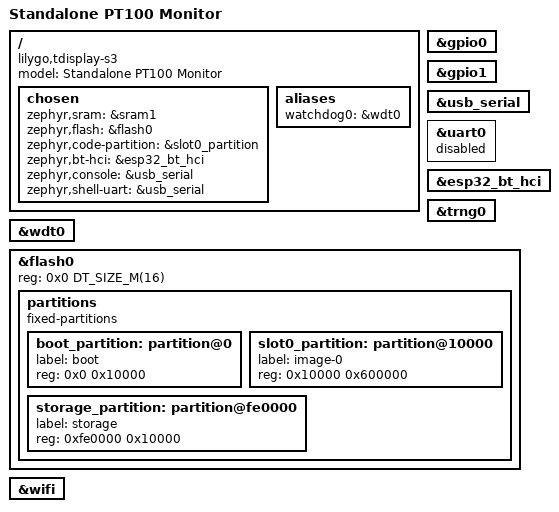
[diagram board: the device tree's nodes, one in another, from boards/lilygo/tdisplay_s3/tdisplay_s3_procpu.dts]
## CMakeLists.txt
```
cmake_minimum_required(VERSION 3.20.0)
# Validate on every configure, including direct west/CMake builds.
find_program(PROBE_CONFIG_PYTHON NAMES python3 REQUIRED)
execute_process(COMMAND ${PROBE_CONFIG_PYTHON} ${CMAKE_CURRENT_SOURCE_DIR}/tools/configure.py
  RESULT_VARIABLE PROBE_CONFIG_RESULT)
if(NOT PROBE_CONFIG_RESULT EQUAL 0)
  message(FATAL_ERROR "Fill config/device.json before building or flashing (see README.md).")
endif()
list(APPEND BOARD_ROOT ${CMAKE_CURRENT_SOURCE_DIR})
find_package(Zephyr REQUIRED HINTS $ENV{ZEPHYR_BASE})
project(thermal_probe)
target_sources(app PRIVATE src/main.c src/wireless.c src/modbus_codec.c src/http_request.c src/filter.c src/format.c)
target_sources_ifdef(CONFIG_THERMAL_DISPLAY app PRIVATE src/display.c src/tdisplay_lcd.c)
target_include_directories(app PRIVATE ${CMAKE_CURRENT_SOURCE_DIR}/local)
```

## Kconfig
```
mainmenu "Thermal Probe"

source "Kconfig.zephyr"

menu "Thermal Probe options"

config THERMAL_DISPLAY
    bool "Enable the tested ST7789 panel and GPIO14 controls"
    default y
    help
      Disable for a headless build on the same supported ESP32-S3 board.
      Sensor, power enable and network behavior remain unchanged.

endmenu
```

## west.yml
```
manifest:
  projects:
    - name: zephyr
      url: https://github.com/zephyrproject-rtos/zephyr
      revision: v4.1.0
      import:
        name-allowlist:
          - hal_espressif
          - hal_xtensa
          - mbedtls
  self:
    path: thermal-probe
```

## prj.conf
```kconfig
CONFIG_GPIO=y
CONFIG_MAIN_STACK_SIZE=8192
CONFIG_NEWLIB_LIBC=y
CONFIG_NEWLIB_LIBC_FLOAT_PRINTF=y
CONFIG_BUILD_OUTPUT_BIN=y
CONFIG_ESP_SIMPLE_BOOT=y
CONFIG_BOOTLOADER_MCUBOOT=n
CONFIG_SMP=n
CONFIG_ESPTOOLPY_FLASHSIZE_16MB=y
CONFIG_ESPTOOLPY_FLASHFREQ_40M=y
CONFIG_BT=n
CONFIG_WIFI=y
CONFIG_ESP_SPIRAM=n
CONFIG_HEAP_MEM_POOL_SIZE=98304

CONFIG_NETWORKING=y
CONFIG_NET_IPV4=y
CONFIG_NET_IPV6=n
CONFIG_NET_TCP=y
CONFIG_NET_UDP=y
CONFIG_NET_DHCPV4=y
CONFIG_NET_SOCKETS=y
CONFIG_NET_MGMT=y
CONFIG_NET_MGMT_EVENT=y
CONFIG_NET_MGMT_EVENT_INFO=y
CONFIG_ESP32_WIFI_STA_AUTO_DHCPV4=y
CONFIG_ESP32_WIFI_STA_RECONNECT=y
CONFIG_NET_MAX_CONTEXTS=32
CONFIG_NET_PKT_RX_COUNT=48
CONFIG_NET_PKT_TX_COUNT=48
CONFIG_NET_BUF_RX_COUNT=64
CONFIG_NET_BUF_TX_COUNT=64

CONFIG_NET_L2_ETHERNET=y

# Two listeners, six clients, DHCP and reconnect headroom.
CONFIG_ZVFS_OPEN_MAX=16
CONFIG_NET_MAX_CONN=32

# Required for worker timeout/slot reclamation; setsockopt otherwise fails.
CONFIG_NET_CONTEXT_RCVTIMEO=y
CONFIG_NET_CONTEXT_SNDTIMEO=y

# LAN discovery and serial diagnostics.
CONFIG_NET_ARP_TABLE_SIZE=8
CONFIG_NET_ARP_GRATUITOUS_TRANSMISSION=y
CONFIG_NET_ARP_GRATUITOUS_INTERVAL=10
CONFIG_NET_STATISTICS=y
CONFIG_NET_STATISTICS_USER_API=y

CONFIG_LOG=y
CONFIG_LOG_DEFAULT_LEVEL=2
CONFIG_LOG_BUFFER_SIZE=2048
CONFIG_LOG_PROCESS_THREAD_STACK_SIZE=2048
CONFIG_NET_LOG=y
CONFIG_NET_ARP_LOG_LEVEL_WRN=y
CONFIG_NET_TCP_LOG_LEVEL_WRN=y

# Each TCP context reserves RX/TX packet descriptors, including listeners.
# Leave descriptors and full Ethernet frame buffers available during reconnects.
CONFIG_NET_BUF_DATA_SIZE=256
CONFIG_NET_TCP_MAX_RECV_WINDOW_SIZE=1280
CONFIG_NET_TCP_MAX_SEND_WINDOW_SIZE=1280
CONFIG_NET_TCP_RETRY_COUNT=3
```

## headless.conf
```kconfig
# Same board and sensor contract; omit panel driver, UI thread and history.
CONFIG_THERMAL_DISPLAY=n
```

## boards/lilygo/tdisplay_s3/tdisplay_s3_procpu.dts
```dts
/dts-v1/;
#include <espressif/esp32s3/esp32s3_wroom_n8.dtsi>
#include <zephyr/dt-bindings/gpio/gpio.h>

/ {
    model = "Standalone PT100 Monitor";
    compatible = "lilygo,tdisplay-s3";
    chosen {
        zephyr,sram = &sram1;
        zephyr,flash = &flash0;
        zephyr,code-partition = &slot0_partition;
        zephyr,bt-hci = &esp32_bt_hci;
        zephyr,console = &usb_serial;
        zephyr,shell-uart = &usb_serial;

    };
    aliases { watchdog0 = &wdt0; };

};
&gpio0 { status = "okay"; };
&gpio1 { status = "okay"; };
&usb_serial { status = "okay"; };
&uart0 { status = "disabled"; };
&esp32_bt_hci { status = "okay"; };
&trng0 { status = "okay"; };
&wdt0 { status = "okay"; };
&flash0 {
    reg = <0x0 DT_SIZE_M(16)>;
    partitions {
        compatible = "fixed-partitions";
        #address-cells = <1>; #size-cells = <1>;
        boot_partition: partition@0 { label = "boot"; reg = <0x0 0x10000>; };
        slot0_partition: partition@10000 { label = "image-0"; reg = <0x10000 0x600000>; };
        storage_partition: partition@fe0000 { label = "storage"; reg = <0xfe0000 0x10000>; };
    };
};

&wifi { status = "okay"; };
```

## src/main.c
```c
#include <zephyr/kernel.h>
#include <zephyr/drivers/gpio.h>
#include <math.h>
#include "format.h"
#include <stdlib.h>
#include <string.h>
#include "wireless.h"
#include "filter.h"
#include "display.h"

static const struct device *gpio=DEVICE_DT_GET(DT_NODELABEL(gpio0));
enum {CS=10,MOSI=11,SCK=12,MISO=13,BUTTON=14};
static void set(int p,int v){gpio_pin_set(gpio,p,v);}
/* MAX31865 SPI mode 1: clock idle low, data sampled on falling edge. */
static unsigned transfer(unsigned v){unsigned r=0;for(int i=7;i>=0;i--){set(SCK,1);set(MOSI,(v>>i)&1);k_busy_wait(2);set(SCK,0);k_busy_wait(2);r=(r<<1)|(gpio_pin_get(gpio,MISO)>0);}return r;}
static void write_reg(unsigned addr,unsigned val){set(CS,0);transfer(addr|128);transfer(val);set(CS,1);}
static unsigned read_reg(unsigned addr){set(CS,0);transfer(addr);unsigned r=transfer(0);set(CS,1);return r;}
static bool temperature(double *t){
 /* Bias + continuous + 3-wire + 50 Hz mains rejection. Readback catches missing chip. */
 if((read_reg(0)&0xd1)!=0xd1){write_reg(0,0xd3);return false;}
 set(CS,0);transfer(1);unsigned raw=transfer(0)<<8;raw|=transfer(0);set(CS,1);
 if((raw&1)||read_reg(7)){write_reg(0,0xd3);return false;}
 double r=(raw>>1)*430.0/32768.0;
 if(r<18.5||r>390.5)return false;
 /* Invert IEC 60751 including the negative-temperature C term. */
 double lo=-200,hi=850;
 for(int i=0;i<32;i++){double x=(lo+hi)/2;double rr=100*(1+3.9083e-3*x-5.775e-7*x*x+(x<0?-4.183e-12*(x-100)*x*x*x:0));if(rr<r)lo=x;else hi=x;}
 *t=(lo+hi)/2;return true;
}
int main(void){
 gpio_pin_configure(gpio,15,GPIO_OUTPUT_HIGH);
 gpio_pin_configure(gpio,CS,GPIO_OUTPUT_HIGH);gpio_pin_configure(gpio,MOSI,GPIO_OUTPUT_LOW);gpio_pin_configure(gpio,SCK,GPIO_OUTPUT_LOW);gpio_pin_configure(gpio,MISO,GPIO_INPUT|GPIO_PULL_DOWN);
 write_reg(3,0xff);write_reg(4,0xff);write_reg(5,0);write_reg(6,0);write_reg(0,0xd3);k_msleep(100);
 wireless_start();display_start();struct filter f={0};int64_t next=k_uptime_get();
 for(;;){int64_t now=k_uptime_get();double raw=NAN,smooth=NAN,d1=NAN,d2=NAN;bool valid=temperature(&raw),ready=false;
 if(valid){smooth=raw;ready=filter_push(&f,now/1000.0,raw,&smooth,&d1,&d2);}else f.n=0;
 wireless_sample(raw,smooth,d1,d2,valid,ready);
 display_sample(smooth,d1,d2,valid,ready);
 if(valid)probe_printf("PT100 t_ms=%lld raw=%.3f C smooth=%.3f C d1=%.5f d2=%.6f ready=%d\n",(long long)now,raw,smooth,d1,d2,ready);else probe_printf("PT100 SENSOR_ERROR\n");
 next+=100;if(next<=k_uptime_get())next=k_uptime_get()+100;k_sleep(K_TIMEOUT_ABS_MS(next));}
}
```

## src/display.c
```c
/* Local display owns the LCD and local curve; sampling/network remain independent. */
#include <zephyr/kernel.h>
#include <zephyr/drivers/gpio.h>
#include <zephyr/net/net_if.h>
#include <zephyr/net/socket.h>
#include <math.h>
#include "format.h"
#include <stdlib.h>
#include <string.h>
#include "tdisplay_lcd.h"
#include "display.h"
#include "drawing.h"
#define HISTORY 600
#define BAND_HEIGHT 4
#define COLOR_BACKGROUND 0x0882
#define COLOR_PLOT 0x10c4
#define COLOR_INK 0xe77e
#define COLOR_MUTED 0x8cb3
#define COLOR_LINE 0x31a7
#define COLOR_ACCENT 0x5d3f
#define COLOR_ERROR 0xf36b
#define COLOR_GREEN 0x3dca
K_MUTEX_DEFINE(display_lock);
static struct {double temperature,d1,d2;bool valid,ready;int64_t at;} latest;
static int16_t values[HISTORY];
static uint32_t times[HISTORY];
static unsigned count,head;
static uint8_t pixels[320*BAND_HEIGHT*2];
static bool running=true;
static int64_t accumulated,started;
void display_sample(double temperature,double d1,double d2,bool valid,bool ready){
 k_mutex_lock(&display_lock,K_FOREVER);
 latest.temperature=temperature;latest.d1=d1;latest.d2=d2;latest.valid=valid;latest.ready=ready;latest.at=k_uptime_get();
 k_mutex_unlock(&display_lock);
}
static void draw(int64_t now){
 double temperature,d1,d2;bool valid,ready;
 k_mutex_lock(&display_lock,K_FOREVER);
 temperature=latest.temperature;d1=latest.d1;d2=latest.d2;valid=latest.valid&&now-latest.at<2000;ready=latest.ready;
 k_mutex_unlock(&display_lock);
 unsigned elapsed=(accumulated+(running?now-started:0))/1000;
 char ip[NET_IPV4_ADDR_LEN]="WIFI CONNECTING";
 struct net_if *iface=net_if_get_default();
 const struct in_addr *addr=iface?net_if_ipv4_get_global_addr(iface,NET_ADDR_PREFERRED):NULL;
 if(addr)net_addr_ntop(AF_INET,addr,ip,sizeof ip);
 double low=0,high=250;
 for(unsigned i=0;i<count;i++){int16_t stored=values[(head+HISTORY-count+i)%HISTORY];double v=stored/10.0;if(stored!=INT16_MIN){if(v<low)low=floor(v/50)*50;if(v>high)high=ceil(v/50)*50;}}
 double first=count?times[(head+HISTORY-count)%HISTORY]:0,last=count?times[(head+HISTORY-1)%HISTORY]:0;
 /* Labels are constant for the whole frame, not recalculated for every band. */
 char timer_text[32],temperature_text[64],d1_text[64],d2_text[64],axis_text[3][32];
 probe_snprintf(timer_text,sizeof timer_text,"%s %02u:%02u",running?"LIVE":"HOLD",elapsed/60,elapsed%60);
 if(valid)probe_snprintf(temperature_text,sizeof temperature_text,"%.1f C",temperature);else probe_snprintf(temperature_text,sizeof temperature_text,"SENSOR ERROR");
 if(valid&&ready)probe_snprintf(d1_text,sizeof d1_text,"D1: %.2f C/MIN",d1*60.0);else probe_snprintf(d1_text,sizeof d1_text,"D1: -- C/MIN");
 if(valid&&ready)probe_snprintf(d2_text,sizeof d2_text,"D2: %.2f C/MIN2",d2*3600.0);else probe_snprintf(d2_text,sizeof d2_text,"D2: -- C/MIN2");
 for(int j=0;j<3;j++)probe_snprintf(axis_text[j],sizeof axis_text[j],"%.0f",high-(high-low)*j/2);
 for(int y=0;y<170;y+=BAND_HEIGHT){
 unsigned height=170-y<BAND_HEIGHT?170-y:BAND_HEIGHT;
 for(unsigned i=0;i<sizeof pixels;i+=2){pixels[i]=COLOR_BACKGROUND>>8;pixels[i+1]=COLOR_BACKGROUND&255;}struct canvas c={pixels,y,height};
 rect(&c,0,49,320,92,COLOR_PLOT);rect(&c,0,13,320,1,COLOR_LINE);rect(&c,161,18,1,24,COLOR_LINE);
 text(&c,5,3,"PT100 / WIFI",1,COLOR_INK);
 text(&c,222,3,timer_text,1,running?COLOR_GREEN:COLOR_MUTED);
 text(&c,5,18,temperature_text,2,valid?COLOR_INK:COLOR_ERROR);
 text(&c,170,20,d1_text,1,COLOR_INK);
 text(&c,170,32,d2_text,1,COLOR_ACCENT);
 for(int j=0;j<3;j++){text(&c,2,53+j*40,axis_text[j],1,COLOR_MUTED);rect(&c,28,56+j*40,288,1,COLOR_LINE);}
 int px=-1,py=0;
 for(unsigned i=0;i<count;i++){
 unsigned index=(head+HISTORY-count+i)%HISTORY;double v=values[index]/10.0;if(values[index]==INT16_MIN){px=-1;continue;}
 int xx=28+(last>first?(int)((times[index]-first)*287/(last-first)):0),yy=136-(v-low)*80/(high-low);
 if(px>=0){int steps=abs(xx-px)>abs(yy-py)?abs(xx-px):abs(yy-py);for(int j=0;j<=steps;j++)rect(&c,steps?px+(xx-px)*j/steps:xx,steps?py+(yy-py)*j/steps:yy,1,1,COLOR_ACCENT);}
 rect(&c,xx,yy,1,1,COLOR_ACCENT);px=xx;py=yy;
 }
 text(&c,5,145,ip,1,addr?COLOR_MUTED:COLOR_ACCENT);
 text(&c,5,159,"10HZ / TAP HOLD / HOLD 2S CLEAR",1,COLOR_MUTED);
 tdisplay_lcd_band(y,height,pixels);
 }
}
static void ui(void *a,void *b,void *c){
 const struct device *gpio=DEVICE_DT_GET(DT_NODELABEL(gpio0));
 int rc=tdisplay_lcd_init();probe_printf("DISPLAY init=%d 320x170\n",rc);if(rc)return;
 rc=gpio_pin_configure(gpio,14,GPIO_INPUT|GPIO_PULL_UP);if(rc){probe_printf("DISPLAY button init=%d\n",rc);return;}
 started=k_uptime_get();int last=1,stable=1;int64_t changed=started,pressed=0,next_draw=started,next_history=started;
 for(;;){int64_t now=k_uptime_get();int button=gpio_pin_get(gpio,14);
 if(button>=0){if(button!=last){last=button;changed=now;}if(button!=stable&&now-changed>=30){stable=button;if(!button)pressed=now;else if(now-pressed>=2000){head=count=0;accumulated=0;started=now;next_history=now;probe_printf("DISPLAY local curve cleared\n");}else{if(running)accumulated+=now-started;else started=now;running=!running;next_history=now;probe_printf("DISPLAY curve=%s; acquisition remains 10Hz\n",running?"LIVE":"HOLD");}}}
 if(running&&now>=next_history){k_mutex_lock(&display_lock,K_FOREVER);values[head]=latest.valid&&now-latest.at<2000?(int16_t)lround(latest.temperature*10):INT16_MIN;k_mutex_unlock(&display_lock);times[head]=(accumulated+now-started)/1000.0;head=(head+1)%HISTORY;if(count<HISTORY)count++;next_history=now+3000;}
 if(now>=next_draw){draw(now);next_draw=k_uptime_get()+500;}
 k_msleep(10);
 }
}
K_THREAD_STACK_DEFINE(ui_stack,4096);
static struct k_thread ui_thread;
void display_start(void){k_thread_create(&ui_thread,ui_stack,K_THREAD_STACK_SIZEOF(ui_stack),ui,NULL,NULL,NULL,12,0,K_NO_WAIT);}
```

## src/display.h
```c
#pragma once
#include <stdbool.h>
#ifdef CONFIG_THERMAL_DISPLAY
void display_start(void);
void display_sample(double temperature,double d1,double d2,bool valid,bool ready);
#else
static inline void display_start(void) {}
static inline void display_sample(double temperature,double d1,double d2,bool valid,bool ready) {
 (void)temperature;(void)d1;(void)d2;(void)valid;(void)ready;
}
#endif
```

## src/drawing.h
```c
#define ADV_WIDTH 320
static const char chars[] = "ABCDEFGHIJKLMNOPQRSTUVWXYZ0123456789:-/.?%~";
static const uint8_t glyphs[][7] = {
 {14,17,17,31,17,17,17},{30,17,17,30,17,17,30},{14,17,16,16,16,17,14},
 {30,17,17,17,17,17,30},{31,16,16,30,16,16,31},{31,16,16,30,16,16,16},
 {14,17,16,23,17,17,14},{17,17,17,31,17,17,17},{14,4,4,4,4,4,14},
 {7,2,2,2,2,18,12},{17,18,20,24,20,18,17},{16,16,16,16,16,16,31},
 {17,27,21,21,17,17,17},{17,25,21,19,17,17,17},{14,17,17,17,17,17,14},
 {30,17,17,30,16,16,16},{14,17,17,17,21,18,13},{30,17,17,30,20,18,17},
 {15,16,16,14,1,1,30},{31,4,4,4,4,4,4},{17,17,17,17,17,17,14},
 {17,17,17,17,17,10,4},{17,17,17,21,21,21,10},{17,17,10,4,10,17,17},
 {17,17,10,4,4,4,4},{31,1,2,4,8,16,31},
 {14,17,19,21,25,17,14},{4,12,4,4,4,4,14},{14,17,1,2,4,8,31},
 {30,1,1,14,1,1,30},{2,6,10,18,31,2,2},{31,16,16,30,1,1,30},
 {14,16,16,30,17,17,14},{31,1,2,4,8,8,8},{14,17,17,14,17,17,14},
 {14,17,17,15,1,1,14},{0,4,4,0,4,4,0},{0,0,0,31,0,0,0},
 {1,1,2,4,8,16,16},{0,0,0,0,0,6,6},{14,17,1,2,4,0,4},
 {25,26,2,4,8,11,19},{0,0,9,22,0,0,0},
};
struct canvas { uint8_t *pixels; int y, height; };
static void rect(struct canvas *c, int x, int y, int w, int h, uint16_t color) {
    int x0=x<0?0:x, x1=x+w>ADV_WIDTH?ADV_WIDTH:x+w;
    int y0=y<c->y?c->y:y, y1=y+h>c->y+c->height?c->y+c->height:y+h;
    for(int row=y0;row<y1;row++) for(int col=x0;col<x1;col++) {
        size_t p=((row-c->y)*ADV_WIDTH+col)*2;
        c->pixels[p]=color>>8; c->pixels[p+1]=color&255;
    }
}
static void text(struct canvas *c,int x,int y,const char *s,int scale,uint16_t color) {
    for(;*s;s++,x+=6*scale) {
        const char *g=strchr(chars,*s);
        if(!g || *s==' ') continue;
        const uint8_t *rows=glyphs[g-chars];
        for(int yy=0;yy<7;yy++) for(int xx=0;xx<5;xx++)
            if(rows[yy]&(1<<(4-xx)))rect(c,x+xx*scale,y+yy*scale,scale,scale,color);
    }
}
```

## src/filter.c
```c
#include "filter.h"
#include <math.h>
#include <string.h>
/* Causal quadratic least squares, using actual seconds relative to newest sample.
 * Derivatives are evaluated at the newest timestamp (not at window centre). */
bool filter_push(struct filter *f,double t,double v,double *smooth,double *d1,double *d2){
 if(!isfinite(t)||!isfinite(v)){f->n=0;return false;}
 if(f->n && (t<=f->t[f->n-1] || t-f->t[f->n-1]>1.5))f->n=0;
 if(f->n==FILTER_N){memmove(f->t,f->t+1,(FILTER_N-1)*sizeof(double));memmove(f->v,f->v+1,(FILTER_N-1)*sizeof(double));f->n--;}
 f->t[f->n]=t;f->v[f->n++]=v;*smooth=v;
 if(f->n<FILTER_N)return false;
 double a[3][4]={0};
 for(int k=0;k<f->n;k++){double x=f->t[k]-t,p[5]={1};for(int j=1;j<5;j++)p[j]=p[j-1]*x;for(int i=0;i<3;i++){for(int j=0;j<3;j++)a[i][j]+=p[i+j];a[i][3]+=p[i]*f->v[k];}}
 for(int i=0;i<3;i++){int best=i;for(int k=i+1;k<3;k++)if(fabs(a[k][i])>fabs(a[best][i]))best=k;for(int j=0;j<4;j++){double tmp=a[i][j];a[i][j]=a[best][j];a[best][j]=tmp;}double div=a[i][i];if(fabs(div)<1e-10)return false;for(int j=i;j<4;j++)a[i][j]/=div;for(int k=0;k<3;k++)if(k!=i){double q=a[k][i];for(int j=i;j<4;j++)a[k][j]-=q*a[i][j];}}
 *smooth=a[0][3];*d1=a[1][3];*d2=2*a[2][3];return true;
}
```

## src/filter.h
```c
#pragma once
#include <stdbool.h>
#define FILTER_N 101 /* 10 seconds at 10 Hz, including both endpoints. */
struct filter { double t[FILTER_N],v[FILTER_N]; int n; };
bool filter_push(struct filter *f,double t,double v,double *smooth,double *d1,double *d2);
```

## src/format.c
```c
#include "format.h"
#include <zephyr/kernel.h>
#include <stdarg.h>
#include <stdio.h>

K_MUTEX_DEFINE(format_lock);

static int format_buffer(char *buffer, size_t size, const char *format, va_list args)
{
    /* printf's stdout lock does not protect snprintf's separate FILE object.
     * Both nevertheless use the same newlib _impure_ptr/dtoa scratch state. */
    k_mutex_lock(&format_lock, K_FOREVER);
    int length = vsnprintf(buffer, size, format, args);
    k_mutex_unlock(&format_lock);
    return length;
}

int probe_snprintf(char *buffer, size_t size, const char *format, ...)
{
    va_list args;
    va_start(args, format);
    int length = format_buffer(buffer, size, format, args);
    va_end(args);
    return length;
}

int probe_printf(const char *format, ...)
{
    char buffer[256];
    va_list args;
    va_start(args, format);
    int length = format_buffer(buffer, sizeof buffer, format, args);
    va_end(args);
    if (length < 0 || (size_t)length >= sizeof buffer) {
        return -1;
    }
    /* USB console can wait for the host. Never hold the formatting lock
     * during console I/O, so a disconnected console cannot block HTTP/UI. */
    return fwrite(buffer, 1, (size_t)length, stdout) == (size_t)length ? length : -1;
}
```

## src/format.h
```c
#ifndef PROBE_FORMAT_H
#define PROBE_FORMAT_H

#include <stddef.h>

/* Serialize application formatting: SDK newlib shares its dtoa work area.
 * These functions are for threads, not ISRs. No sample/display lock is taken. */
int probe_snprintf(char *buffer, size_t size, const char *format, ...)
    __attribute__((format(printf, 3, 4)));

/* Formats at most 255 bytes before releasing the format lock and writing to
 * stdout. Returns -1 on formatting error, truncation, or a short console write. */
int probe_printf(const char *format, ...)
    __attribute__((format(printf, 1, 2)));

#endif
```

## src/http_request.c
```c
#include "http_request.h"
#include <string.h>

enum http_request_result http_request_parse(const char *data, size_t length)
{
    size_t end = 0, line = 0;
    for (size_t i = 0; i < length; ++i) {
        if (!data[i]) return HTTP_REQUEST_BAD;
        if (i >= 3 && !memcmp(data + i - 3, "\r\n\r\n", 4)) {
            end = i + 1;
            break;
        }
    }
    if (!end) return length >= HTTP_REQUEST_LIMIT
        ? HTTP_REQUEST_TOO_LARGE : HTTP_REQUEST_INCOMPLETE;
    if (end > HTTP_REQUEST_LIMIT) return HTTP_REQUEST_TOO_LARGE;
    while (line + 1 < end && memcmp(data + line, "\r\n", 2)) ++line;
    if (line < 9 || (memcmp(data + line - 9, " HTTP/1.1", 9) &&
                     memcmp(data + line - 9, " HTTP/1.0", 9))) {
        return HTTP_REQUEST_BAD;
    }
    size_t target_length = line - 9;
    if ((target_length == 20 && !memcmp(data, "GET /api/temperature", 20)) ||
        (target_length == 5 && !memcmp(data, "GET /", 5))) {
        return HTTP_REQUEST_TEMPERATURE;
    }
    return HTTP_REQUEST_NOT_FOUND;
}
```

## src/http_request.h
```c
#pragma once
#include <stddef.h>

#define HTTP_REQUEST_LIMIT 512
enum http_request_result {
    HTTP_REQUEST_INCOMPLETE,
    HTTP_REQUEST_TEMPERATURE,
    HTTP_REQUEST_NOT_FOUND,
    HTTP_REQUEST_BAD,
    HTTP_REQUEST_TOO_LARGE
};
/* Parse a bounded, not necessarily NUL-terminated TCP receive buffer. */
enum http_request_result http_request_parse(const char *data, size_t length);
```

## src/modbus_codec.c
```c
#include "modbus_codec.h"
#include <string.h>
static unsigned be16(const uint8_t *p){return (p[0]<<8)|p[1];}
size_t modbus_reply(const uint8_t *q,size_t n,uint8_t *r,const uint16_t regs[8],int valid,int ready){
 if(n<8||n>260||be16(q+2)!=0||be16(q+4)!=n-6)return 0;
 memcpy(r,q,8);unsigned code=0,addr=0,count=0;
 if(q[6]!=1)code=11;
 else if(q[7]!=3&&q[7]!=4)code=1;
 else if(n!=12)code=3;
 else {addr=be16(q+8);count=be16(q+10);
 if(!count||count>125)code=3;
 else if(addr>=8||count>8-addr)code=2;
 else if(!valid||(!ready&&addr+count>4))code=4;}
 if(code){r[4]=0;r[5]=3;r[7]|=128;r[8]=code;return 9;}
 r[4]=0;r[5]=3+count*2;r[8]=count*2;
 for(unsigned i=0;i<count;i++){r[9+i*2]=regs[addr+i]>>8;r[10+i*2]=regs[addr+i];}
 return 9+count*2;
}
```

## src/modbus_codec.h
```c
#pragma once
#include <stddef.h>
#include <stdint.h>
/* Complete MBAP-framed request to response; snapshot = four big-endian floats. */
size_t modbus_reply(const uint8_t *q, size_t n, uint8_t *r, const uint16_t regs[8], int valid, int ready);
```

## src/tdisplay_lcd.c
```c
/* SPDX-License-Identifier: MIT
 * ST7789 8-bit 8080 bus, T-Display S3 pinout. Single UI-thread owner.
 * GPIO bank writes avoid a slow per-pin API on each pixel. No IRQ masking:
 * the display permits idle pauses between strobes, so BLE/USB keep running.
 */
#include <zephyr/kernel.h>
#include <zephyr/drivers/gpio.h>
#include <soc/gpio_struct.h>
#include "tdisplay_lcd.h"
#define ADV_WIDTH 320
#define ADV_HEIGHT 170
static const struct device *g0=DEVICE_DT_GET(DT_NODELABEL(gpio0));
static const struct device *g1=DEVICE_DT_GET(DT_NODELABEL(gpio1));
static const unsigned data_pins[]={39,40,41,42,45,46,47,48};
static uint32_t data_bits[256];
#define DATA_MASK ((15u<<7)|(15u<<13))
static inline void level(unsigned pin,bool high) {
    if(pin<32){if(high)GPIO.out_w1ts=1u<<pin;else GPIO.out_w1tc=1u<<pin;}
    else {if(high)GPIO.out1_w1ts.val=1u<<(pin-32);else GPIO.out1_w1tc.val=1u<<(pin-32);}
}
static inline void byte(uint8_t b) {
    level(8,false);GPIO.out1_w1tc.val=DATA_MASK;GPIO.out1_w1ts.val=data_bits[b];
    __asm__ volatile("memw; nop; nop; nop" ::: "memory");
    level(8,true);
    __asm__ volatile("memw; nop; nop; nop" ::: "memory");
}
static void command(uint8_t c,const uint8_t *data,unsigned n) {
    level(6,false);level(7,false);byte(c);level(7,true);
    for(unsigned i=0;i<n;i++)byte(data[i]);
    level(6,true);
}
static void window(unsigned x,unsigned y,unsigned w,unsigned h) {
    /* Landscape: visible rows begin at controller row 35. */
    y+=35;
    uint8_t cols[]={x>>8,x,(x+w-1)>>8,x+w-1};
    uint8_t rows[]={y>>8,y,(y+h-1)>>8,y+h-1};
    command(0x2a,cols,4);command(0x2b,rows,4);command(0x2c,NULL,0);
}
int tdisplay_lcd_init(void) {
    if(!device_is_ready(g0)||!device_is_ready(g1))return -ENODEV;
    const unsigned controls[]={5,6,7,8,9,15,38};
    for(unsigned i=0;i<sizeof(controls)/sizeof(*controls);i++) {
        unsigned p=controls[i];int e=gpio_pin_configure(p<32?g0:g1,p%32,GPIO_OUTPUT_HIGH);if(e)return e;
    }
    level(38,false);
    for(unsigned i=0;i<8;i++){int e=gpio_pin_configure(g1,data_pins[i]-32,GPIO_OUTPUT_LOW);if(e)return e;}
    for(unsigned b=0;b<256;b++)for(unsigned i=0;i<8;i++)if(b&(1u<<i))data_bits[b]|=1u<<(data_pins[i]-32);
    level(5,false);k_msleep(20);level(5,true);k_msleep(120);
    command(0x01,NULL,0);k_msleep(150);command(0x11,NULL,0);k_msleep(120);
    const uint8_t fmt=0x55,rotation=0x60;
    command(0x3a,&fmt,1);command(0x36,&rotation,1);
    command(0x21,NULL,0);command(0x13,NULL,0);command(0x29,NULL,0);k_msleep(20);
    window(0,0,320,170);level(6,false);
    for(unsigned i=0;i<320*170;i++){byte(0);byte(0);}
    level(6,true);level(38,true);return 0;
}
void tdisplay_lcd_band(unsigned y,unsigned height,const uint8_t *pixels) {
    window((320-ADV_WIDTH)/2,(170-ADV_HEIGHT)/2+y,ADV_WIDTH,height);
    level(6,false);
    for(unsigned i=0;i<ADV_WIDTH*height*2;i++)byte(pixels[i]);
    level(6,true);
}
```
